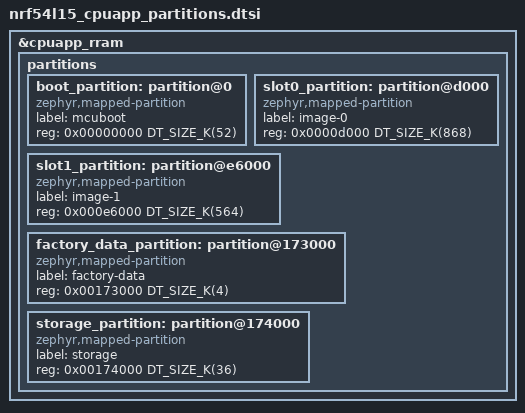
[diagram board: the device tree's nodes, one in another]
/*
 * Copyright (c) 2026 Nordic Semiconductor ASA
 *
 * SPDX-License-Identifier: LicenseRef-Nordic-5-Clause
 */

/*
 * KNX IoT sample partition layout: MCUboot (overwrite-only with compressed
 * update images), primary and secondary application slots in internal RRAM,
 * factory data and settings storage.
 *
 * The secondary slot is sized for an LZMA2-compressed image, assuming roughly
 * 65% compression ratio relative to the primary slot.
 */

/delete-node/ &boot_partition;
/delete-node/ &slot0_partition;
/delete-node/ &slot1_partition;
/delete-node/ &storage_partition;

&cpuapp_rram {
	partitions {
		boot_partition: partition@0 {
			compatible = "zephyr,mapped-partition";
			label = "mcuboot";
			reg = <0x00000000 DT_SIZE_K(52)>;
		};

		slot0_partition: partition@d000 {
			compatible = "zephyr,mapped-partition";
			label = "image-0";
			reg = <0x0000d000 DT_SIZE_K(868)>;
		};

		slot1_partition: partition@e6000 {
			compatible = "zephyr,mapped-partition";
			label = "image-1";
			reg = <0x000e6000 DT_SIZE_K(564)>;
		};

		factory_data_partition: partition@173000 {
			compatible = "zephyr,mapped-partition";
			label = "factory-data";
			reg = <0x00173000 DT_SIZE_K(4)>;
		};

		storage_partition: partition@174000 {
			compatible = "zephyr,mapped-partition";
			label = "storage";
			reg = <0x00174000 DT_SIZE_K(36)>;
		};
	};
};
